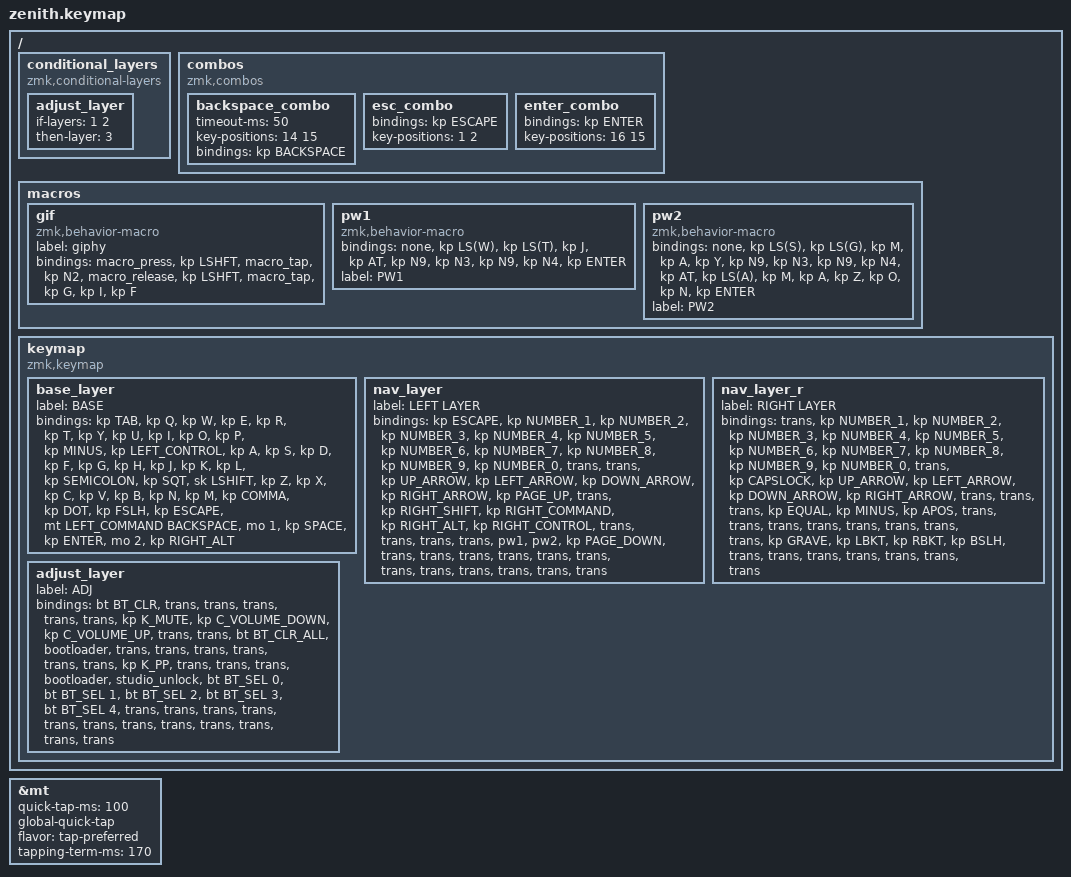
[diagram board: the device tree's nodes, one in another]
//
//                                                        ▀▀▀▀▀     ▀▀▀▀▀          ▀▀█▀▀
//                                                        ▄▀▀▀▄  ▄  ▄▀▀▀▄  ▄  ▄▀▀▀▄  █  ▄▀▀▀▄
//                                                        █   █  █  █   █  █  █   █  █  █   █
//                                                         ▀▀▀   █   ▀▀▀   █   ▀▀▀   ▀   ▀▀▀
//                                                               █      ▄▄▄█▄▄▄    █   █  
//                                                               ▀      █  █  █     █▄█
//                                                             ▀▀▀▀▀    █  █  █      ▀
//                                                                      ▀  ▀  ▀
//
// ▄▄▄▄▄▄▄▄▄▄▄▄▄▄▄▄▄▄▄▄▄▄▄▄▄▄▄▄▄▄▄▄▄▄▄▄▄▄▄▄▄▄▄▄▄▄▄▄▄▄▄▄▄▄▄▄▄▄▄▄▄▄▄▄▄▄▄▄▄▄▄▄▄▄▄▄▄▄▄▄▄▄▄▄▄▄▄▄▄▄▄▄▄▄▄▄▄▄▄▄▄▄▄▄▄▄▄▄▄▄▄▄▄▄▄▄▄▄▄▄▄▄▄▄▄▄▄▄▄▄▄▄▄▄▄▄▄▄▄▄▄▄▄▄▄▄▄▄▄

#include <behaviors.dtsi>
#include <dt-bindings/zmk/bt.h>
#include <dt-bindings/zmk/keys.h>

#define BASE 0
#define NAV  1
#define SYM  2
#define ADJ  3

&mt {
    quick-tap-ms = <100>;
    global-quick-tap;
    flavor = "tap-preferred";
    tapping-term-ms = <170>;
};

/ {
    conditional_layers {
        compatible = "zmk,conditional-layers";

        adjust_layer {
            if-layers = <1 2>;
            then-layer = <3>;
        };
    };

    combos {
        compatible = "zmk,combos";

        backspace_combo {
            timeout-ms = <50>;
            key-positions = <14 15>;
            bindings = <&kp BACKSPACE>;
        };

        esc_combo {
            bindings = <&kp ESCAPE>;
            key-positions = <1 2>;
        };

        enter_combo {
            bindings = <&kp ENTER>;
            key-positions = <16 15>;
        };
    };

    macros {
        gif: gif {
            label = "giphy";
            compatible = "zmk,behavior-macro";
            #binding-cells = <0>;
            bindings =
                <&macro_press>,
                <&kp LSHFT>,
                <&macro_tap>,
                <&kp N2>,
                <&macro_release>,
                <&kp LSHFT>,
                <&macro_tap>,
                <&kp G &kp I &kp F>;
        };

        pw1: pw1 {
            compatible = "zmk,behavior-macro";
            #binding-cells = <0>;
            bindings = <&none &kp LS(W) &kp LS(T) &kp J &kp AT &kp N9 &kp N3 &kp N9 &kp N4 &kp ENTER>;
            label = "PW1";
        };

        pw2: pw2 {
            compatible = "zmk,behavior-macro";
            #binding-cells = <0>;
            bindings = <&none &kp LS(S) &kp LS(G) &kp M &kp A &kp Y &kp N9 &kp N3 &kp N9 &kp N4 &kp AT &kp LS(A) &kp M &kp A &kp Z &kp O &kp N &kp ENTER>;
            label = "PW2";
        };
    };

    keymap {
        compatible = "zmk,keymap";

        // ▄▄▄▄▄▄▄▄▄▄▄▄▄▄▄▄▄▄▄▄▄▄▄▄▄▄▄▄▄▄▄▄▄▄▄▄▄▄▄▄▄▄▄▄▄▄▄▄▄▄▄▄▄▄▄▄▄▄▄▄▄▄▄▄▄▄▄▄▄▄▄▄▄▄▄▄▄▄▄▄▄▄▄▄▄▄▄▄▄▄▄▄▄▄▄▄▄▄▄▄▄▄▄▄▄▄▄▄▄▄▄▄▄▄▄▄▄▄▄▄▄▄▄▄▄▄▄▄▄▄▄▄▄▄▄▄▄▄▄▄▄▄▄▄▄▄▄▄▄

        base_layer {
            // ┏━━━━━━━━━━━━━━━━━━━━━━━━━━━━━━━━━━━━━━━┓

            label = "BASE";

            // ┗━━━━━━━━━━━━━━━━━━━━━━━━━━━━━━━━━━━━━━━┛

            bindings = <
&kp TAB  &kp Q  &kp W  &kp E  &kp R  &kp T  &kp Y  &kp U  &kp I  &kp O  &kp P  &kp MINUS  &kp LEFT_CONTROL  &kp A  &kp S  &kp D  &kp F  &kp G  &kp H  &kp J  &kp K  &kp L  &kp SEMICOLON  &kp SQT  &sk LSHIFT  &kp Z  &kp X  &kp C  &kp V  &kp B  &kp N  &kp M  &kp COMMA  &kp DOT  &kp FSLH  &kp ESCAPE  &mt LEFT_COMMAND BACKSPACE  &mo 1  &kp SPACE  &kp ENTER  &mo 2  &kp RIGHT_ALT
            >;
        };

        nav_layer {
            // ┏━━━━━━━━━━━━━━━━━━━━━━━━━━━━━━━━━━━━━━━┓

            label = "LEFT LAYER";

            // ┗━━━━━━━━━━━━━━━━━━━━━━━━━━━━━━━━━━━━━━━┛

            bindings = <
&kp ESCAPE  &kp NUMBER_1  &kp NUMBER_2  &kp NUMBER_3  &kp NUMBER_4  &kp NUMBER_5  &kp NUMBER_6  &kp NUMBER_7  &kp NUMBER_8  &kp NUMBER_9  &kp NUMBER_0  &trans  &trans  &kp UP_ARROW  &kp LEFT_ARROW  &kp DOWN_ARROW  &kp RIGHT_ARROW  &kp PAGE_UP  &trans  &kp RIGHT_SHIFT  &kp RIGHT_COMMAND  &kp RIGHT_ALT  &kp RIGHT_CONTROL  &trans  &trans  &trans  &trans  &pw1  &pw2  &kp PAGE_DOWN  &trans  &trans  &trans  &trans  &trans  &trans  &trans  &trans  &trans  &trans  &trans  &trans
            >;
        };

        nav_layer_r {
            label = "RIGHT LAYER";
            bindings = <
&trans  &kp NUMBER_1  &kp NUMBER_2  &kp NUMBER_3  &kp NUMBER_4  &kp NUMBER_5  &kp NUMBER_6  &kp NUMBER_7  &kp NUMBER_8  &kp NUMBER_9  &kp NUMBER_0  &trans  &kp CAPSLOCK  &kp UP_ARROW  &kp LEFT_ARROW  &kp DOWN_ARROW  &kp RIGHT_ARROW  &trans  &trans  &trans  &kp EQUAL  &kp MINUS  &kp APOS  &trans  &trans  &trans  &trans  &trans  &trans  &trans  &trans  &kp GRAVE  &kp LBKT  &kp RBKT  &kp BSLH  &trans  &trans  &trans  &trans  &trans  &trans  &trans
            >;
        };

        adjust_layer {
            // ┏━━━━━━━━━━━━━━━━━━━━━━━━━━━━━━━━━━━━━━━┓

            label = "ADJ";

            // ┗━━━━━━━━━━━━━━━━━━━━━━━━━━━━━━━━━━━━━━━┛

            bindings = <
&bt BT_CLR  &trans  &trans  &trans  &trans  &trans  &kp K_MUTE  &kp C_VOLUME_DOWN  &kp C_VOLUME_UP  &trans  &trans  &bt BT_CLR_ALL  &bootloader  &trans  &trans  &trans  &trans  &trans  &trans  &kp K_PP  &trans  &trans  &trans  &bootloader  &studio_unlock  &bt BT_SEL 0  &bt BT_SEL 1  &bt BT_SEL 2  &bt BT_SEL 3  &bt BT_SEL 4  &trans  &trans  &trans  &trans  &trans  &trans  &trans  &trans  &trans  &trans  &trans  &trans
            >;
        };
    };
};
